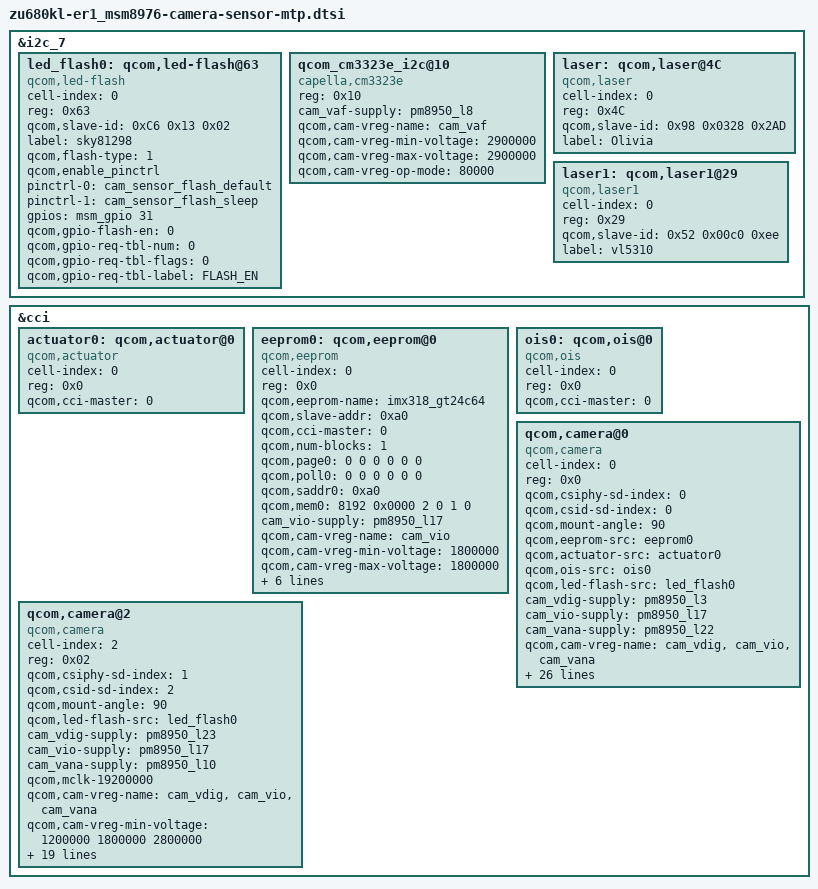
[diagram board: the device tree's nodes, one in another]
/*
 * Copyright (c) 2015, The Linux Foundation. All rights reserved.
 *
 * This program is free software; you can redistribute it and/or modify
 * it under the terms of the GNU General Public License version 2 and
 * only version 2 as published by the Free Software Foundation.
 *
 * This program is distributed in the hope that it will be useful,
 * but WITHOUT ANY WARRANTY; without even the implied warranty of
 * MERCHANTABILITY or FITNESS FOR A PARTICULAR PURPOSE.  See the
 * GNU General Public License for more details.
 */

&i2c_7 {
	led_flash0: qcom,led-flash@63 {
		cell-index = <0>;
		reg = <0x63>;
		qcom,slave-id = <0xC6 0x13 0x02>;
		compatible = "qcom,led-flash";
		label = "sky81298";
		qcom,flash-type = <1>;
		qcom,enable_pinctrl;
		pinctrl-names = "cam_flash_default", "cam_flash_suspend";
		pinctrl-0 = <&cam_sensor_flash_default>;
		pinctrl-1 = <&cam_sensor_flash_sleep>;
		gpios = <&msm_gpio 31 0>;
		qcom,gpio-flash-en = <0>;
		qcom,gpio-req-tbl-num = <0>;
		qcom,gpio-req-tbl-flags = <0>;
		qcom,gpio-req-tbl-label = "FLASH_EN";
	};
	qcom_cm3323e_i2c@10 {
		compatible = "capella,cm3323e";
		reg = <0x10>;
		cam_vaf-supply = <&pm8950_l8>;
		qcom,cam-vreg-name = "cam_vaf";
		qcom,cam-vreg-min-voltage = <2900000>;
		qcom,cam-vreg-max-voltage = <2900000>;
		qcom,cam-vreg-op-mode = <80000>;
	};
	laser: qcom,laser@4C {
		cell-index = <0>;
		reg = <0x4C>;
		qcom,slave-id = <0x98 0x0328 0x2AD>;
		compatible = "qcom,laser";
		label = "Olivia";
	};
	laser1: qcom,laser1@29 {
		cell-index = <0>;
		reg = <0x29>;
		qcom,slave-id = <0x52 0x00c0 0xee>;
		compatible = "qcom,laser1";
		label = "vl5310";
	};
};
&cci {
	actuator0: qcom,actuator@0 {
		cell-index = <0>;
		reg = <0x0>;
		compatible = "qcom,actuator";
		qcom,cci-master = <0>;
	};
	eeprom0: qcom,eeprom@0 {
		cell-index = <0>;
		reg = <0x0>;
		qcom,eeprom-name = "imx318_gt24c64";
		compatible = "qcom,eeprom";
		qcom,slave-addr = <0xa0>;
		qcom,cci-master = <0>;
		qcom,num-blocks = <1>;
		qcom,page0 = <0 0 0 0 0 0>;
		qcom,poll0 = <0 0 0 0 0 0>;
		qcom,saddr0 = <0xa0>;
		qcom,mem0 = <8192 0x0000 2 0 1 0>;
		cam_vio-supply = <&pm8950_l17>;
		qcom,cam-vreg-name = "cam_vio";
		qcom,cam-vreg-min-voltage = <1800000>;
		qcom,cam-vreg-max-voltage = <1800000>;
		qcom,cam-vreg-op-mode = <80000>;
		qcom,cam-power-seq-type = "sensor_vreg";
		qcom,cam-power-seq-val = "cam_vio";
		qcom,cam-power-seq-cfg-val = <1>;
		qcom,cam-power-seq-delay = <1>;
		qcom,i2c-freq-mode = <1>;
		status = "ok";
	};

	ois0: qcom,ois@0 {
		cell-index = <0>;
		reg = <0x0>;
		compatible = "qcom,ois";
		qcom,cci-master = <0>;
	};

	qcom,camera@0 {
		cell-index = <0>;
		compatible = "qcom,camera";
		reg = <0x0>;
		qcom,csiphy-sd-index = <0>;
		qcom,csid-sd-index = <0>;
		qcom,mount-angle = <90>;
		qcom,eeprom-src = <&eeprom0>;
		qcom,actuator-src = <&actuator0>;
		qcom,ois-src = <&ois0>;
		qcom,led-flash-src = <&led_flash0>;
		cam_vdig-supply = <&pm8950_l3>;
		cam_vio-supply = <&pm8950_l17>;
		cam_vana-supply = <&pm8950_l22>;
		qcom,cam-vreg-name = "cam_vdig", "cam_vio", "cam_vana";
		qcom,cam-vreg-min-voltage = <1050000 1800000 2800000>;
		qcom,cam-vreg-max-voltage = <1050000 1800000 2800000>;
		qcom,cam-vreg-op-mode = <105000 80000 80000>;
		pinctrl-names = "cam_default", "cam_suspend";
		pinctrl-0 = <&cam_sensor_mclk0_default &cam_sensor_rear_default &cam_sensor_rear_vana>;
		pinctrl-1 = <&cam_sensor_mclk0_sleep &cam_sensor_rear_sleep &cam_sensor_rear_vana_sleep>;
		gpios = <&msm_gpio 26 0>, <&msm_gpio 35 0>, <&msm_gpio 27 0>, <&msm_gpio 131 0>;
		qcom,gpio-reset = <1>;
		qcom,gpio-vana = <2>;
		qcom,gpio-vaf = <3>;
		qcom,gpio-req-tbl-num = <0 1 2 3>;
		qcom,gpio-req-tbl-flags = <1 0 0 0>;
		qcom,gpio-req-tbl-label = "CAMIF_MCLK0", "CAM_RESET0", "CAM_VANA", "CAM_VAF";
		qcom,sensor-position = <0>;
		qcom,sensor-mode = <0>;
		qcom,cci-master = <0>;
		status = "ok";
		clocks = <&clock_gcc clk_mclk0_clk_src>, <&clock_gcc clk_gcc_camss_mclk0_clk>, <&clock_gcc clk_bimc_usb_clk>;
		clock-names = "cam_src_clk", "cam_clk", "bimc_clk";
	};

	qcom,camera@2 {
		cell-index = <2>;
		compatible = "qcom,camera";
		reg = <0x02>;
		qcom,csiphy-sd-index = <1>;
		qcom,csid-sd-index = <2>;
		qcom,mount-angle = <90>;
		qcom,led-flash-src = <&led_flash0>;
		cam_vdig-supply = <&pm8950_l23>;
		cam_vio-supply = <&pm8950_l17>;
		cam_vana-supply = <&pm8950_l10>;
		qcom,mclk-19200000;
		qcom,cam-vreg-name = "cam_vdig", "cam_vio", "cam_vana";
		qcom,cam-vreg-min-voltage = <1200000 1800000 2800000>;
		qcom,cam-vreg-max-voltage = <1200000 1800000 2800000>;
		qcom,cam-vreg-op-mode = <105000 80000 80000>;
		pinctrl-names = "cam_default", "cam_suspend";
		pinctrl-0 = <&cam_sensor_mclk2_default &cam_sensor_front1_default>;
		pinctrl-1 = <&cam_sensor_mclk2_sleep &cam_sensor_front1_sleep>;
		gpios = <&msm_gpio 28 0>, <&msm_gpio 36 0>;
		qcom,gpio-reset = <1>;
		qcom,gpio-req-tbl-num = <0 1>;
		qcom,gpio-req-tbl-flags = <1 0>;
		qcom,gpio-req-tbl-label = "CAMIF_MCLK2", "CAM_RESET2";
		qcom,sensor-position = <1>;
		qcom,sensor-mode = <0>;
		qcom,cci-master = <0>;
		status = "ok";
		clocks = <&clock_gcc clk_mclk2_clk_src>, <&clock_gcc clk_gcc_camss_mclk2_clk>, <&clock_gcc clk_snoc_usb_clk>;
		clock-names = "cam_src_clk", "cam_clk", "bimc_clk";
	};


};
